# STM32L562 register map
File version: 1.1
Registers are 32-bit, read-write, reset 0x0 unless marked. A register's access mark holds for its fields unless they carry their own. Offsets are from the block's base; lines under a group give offsets from that group; [hi:lo] are bit positions; {n}, {i} and the like mark numbered series; 'fields as' and 'values as' point back to an identical list; <NAME> marks a mode.

## Memory map
0x420C0000 AES size 0x400 — Advanced encryption standard hardware accelerator 1

## Interrupts
93 AES — AES global interrupts

## AES — Advanced encryption standard hardware accelerator 1
Base 0x420C0000
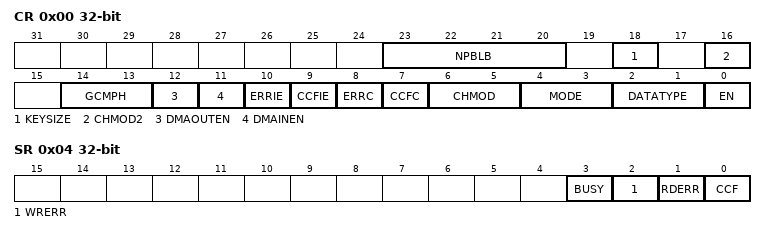
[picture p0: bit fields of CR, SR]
0x00 CR — control register
  [23:20] NPBLB — Number of padding bytes in last block of payload
  [18] KEYSIZE — Key size selection
  [16] CHMOD2 — AES chaining mode Bit2
  [14:13] GCMPH — Used only for GCM, CCM and GMAC algorithms and has no effect when other algorithms are selected
  [12] DMAOUTEN — Enable DMA management of data output phase
  [11] DMAINEN — Enable DMA management of data input phase
  [10] ERRIE — Error interrupt enable
  [9] CCFIE — CCF flag interrupt enable
  [8] ERRC — Error clear
  [7] CCFC — Computation Complete Flag Clear
  [6:5] CHMOD — AES chaining mode selection Bit1 Bit0
  [4:3] MODE — AES operating mode
  [2:1] DATATYPE — Data type selection (for data in and data out to/from the cryptographic block)
  [0] EN — AES enable
0x04 SR ro — status register
  [3] BUSY — Busy flag
  [2] WRERR — Write error flag
  [1] RDERR — Read error flag
  [0] CCF — Computation complete flag
0x08 DINR — data input register
  [31:0] DIN — Data Input Register
0x0C DOUTR ro — data output register
  [31:0] DOUT — Data output register
0x10 KEYRA0 wo — key register 0
  [31:0] KEY — Cryptographic key, bits[31:0]
{0x10+4i} KEYRA{i} wo (i=1..3) — key register {i}
  [31:0] KEY — Cryptographic key, bits [{32i+31}:{32i}])
0x20 IVR0 — initialization vector register 0
  [31:0] IVI — initialization vector register (LSB IVR [31:0])
0x24 IVR1 — initialization vector register 1
  [31:0] IVI — Initialization Vector Register (IVR [63:32])
0x28 IVR2 — initialization vector register 2
  [31:0] IVI — Initialization Vector Register (IVR [95:64])
0x2C IVR3 — initialization vector register 3
  [31:0] IVI — Initialization Vector Register (MSB IVR [127:96])
{0x20+4i} KEYRB{i} wo (i=4..7) — key register {i}
  [31:0] KEY — Cryptographic key, bits [{32i+31}:{32i}])
{0x40+4i} SUSP{i}R (i=0..7) — AES suspend register {i}
  [31:0] AES_SUSP{i}R
